# TZ10xx register map
File version: 0.1g
Registers are 32-bit, read-write, reset 0x0 unless marked. A register's access mark holds for its fields unless they carry their own. Offsets are from the block's base; lines under a group give offsets from that group; [hi:lo] are bit positions; {n}, {i} and the like mark numbered series; 'fields as' and 'values as' point back to an identical list; <NAME> marks a mode.

## Memory map
0x00100000 mpier size 0x10000
0x40000000 pmulv size 0x4000
0x40004000 spic size 0x400
0x40021000 rng size 0x80
0x40022000 sramc size 0x80
0x40023000 evm size 0x40
0x40040000 rtclv size 0x1000
0x40041000 advtmr size 0x1000
0x40042000 tmr size 0x1000
0x40043000 wdt size 0x1000
0x40048000 adcc12 size 0x1000
0x40049000 adcc24 size 0x1000
0x4004A000 gconf size 0x400
0x4004B000 gpio0 size 0x1000
0x4004C000 gpio1 size 0x1000
0x4004D000 gpio2 size 0x1000
0x4004E000 gpio3 size 0x1000
0x40064000 uart0 size 0x1000
0x40065000 uart1 size 0x1000
0x40070000 uart2 size 0x1000
0xE000EF34 fpu size 0x14 — Floating Point system registers

## Interrupts
{n} GPIO_Pin{n} (gpio0) (n=0..7)
{n} GPIO_Pin{n} (gpio1) (n=8..15)
{n} GPIO_Pin{n} (gpio2) (n=16..23)
{n} GPIO_Pin{n} (gpio3) (n=24..31)
39 RTC (rtclv)
40 UART0 (uart0)
41 UART1 (uart1)
42 UART2 (uart2)
44 SRAM_M2M (sramc)
45 SRAM_ERR (sramc)
46 SPIC (spic)
56 ADCC12 (adcc12)
57 ADCC24 (adcc24)
59 WDT (wdt)
60 TMR0 (tmr)
61 TMR1 (tmr)
64 ADVTMR0 (advtmr)
65 ADVTMR1 (advtmr)
66 ADVTMR2 (advtmr)
67 ADVTMR3 (advtmr)
68 ADVTMR0_CAP (advtmr)
69 ADVTMR1_CAP (advtmr)
70 ADVTMR2_CAP (advtmr)
71 ADVTMR3_CAP (advtmr)
72 ADVTMR0_CMP (advtmr)
73 ADVTMR1_CMP (advtmr)
74 ADVTMR2_CMP (advtmr)
75 ADVTMR3_CMP (advtmr)
76 PMU_WKUP (pmulv)
77 BOR (pmulv)
79 FPU (fpu)

## mpier
Base 0x00100000
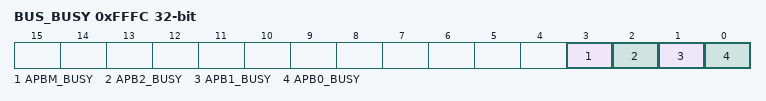
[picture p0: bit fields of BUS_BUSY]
0xFFFC BUS_BUSY ro — Bus busy flag for monitoring whether there are outstanding transactions on APB buses. For detail of procedure for power mode transition using this register, refer to Chapter 2. MCU Power Management Unit.
  [3] APBM_BUSY — APB bus for AESA, RNG, EVM, SRAMC register busy (0x0 : IDLE, 0x1 : BUSY)
  [2] APB2_BUSY — APB2 bus busy (0x0 : IDLE, 0x1 : BUSY)
  [1] APB1_BUSY — APB1 bus busy (0x0 : IDLE, 0x1 : BUSY)
  [0] APB0_BUSY — APB0 bus busy (0x0 : IDLE, 0x1 : BUSY)

## rng
Base 0x40021000
0x00 RNDO ro — Random Number Output Register
  [31:0] RNDO — When [RNDREADY] is 1, 32-bit intrinsic random numbers can be read every time data is read. When [RNDREADY] is 0, 0 can be read. Although this is 0 immediately after reset cancellation, RNDREADY becomes 1 after a while, allowing random numbers to be read through this register.
0x04 RNDREADY ro — Random Number Ready Register
  [0] RNDREADY — 0b0: 0 can be read through [RNDO] because of random numbers being generated. 0b1: Random numbers can be read through [RNDO] since random number generation has been completed. This is 0 immediately after reset cancellation, but becomes 1 after a while.

## sramc
Base 0x40022000
0x00 M2MSTART — M2M activation signal
  [0] START — 1: Activation 0: Invalid * "0" is always returned when data is read
0x04 M2MSTOP
  [0] STOP — 1: Stop 0: Invalid * "0" is always returned when data is read
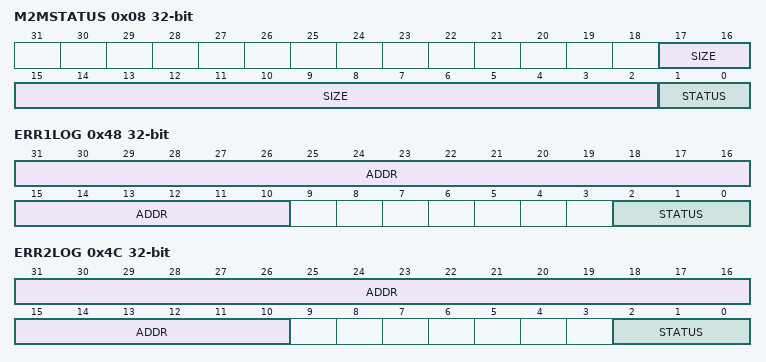
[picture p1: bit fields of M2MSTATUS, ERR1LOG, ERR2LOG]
0x08 M2MSTATUS ro — Status
  [17:2] SIZE — Size of data being currently transferred (amount of data that have been transferred so far)
  [1:0] STATUS — 0b10: Waits for interrupt clearing 0b01: In operation 0b00: Under stop
0x10 M2MSRCADDR — Source address
  [31:2] ADDR — Address from which to read data Set in units of words
0x20 M2MDSTADDR — Destination address
  [31:2] ADDR — Address to which to write data Set in units of words
0x24 M2MSIZE — Transfer size
  [17:2] SIZE — Transfer size settings. The source and destination have the same transfer size. Set in units of words.
0x30 M2MINTEN — Interrupt function ON/OFF
  [0] EN — 1: Interrupt function ON 0: Interrupt function OFF
0x34 M2MINTCLR — Interrupt clearing
  [0] CLR — 1: Activation 0: Invalid * "0" is always returned when data is read.
0x40 ERRINTEN — Error interrupt output function ON/OFF
  [0] EN — 1: Error interrupt output function ON 0: Error interrupt output function OFF
0x44 ERRSTATUS ro — Error cause
  [3:0] STATUS — Error cause indication [3]=1:Error4 occurs [2]=1:Error3 occurs [1]=1:Error2 occurs [0]=1:Error1 occurs
0x48 ERR1LOG ro — Error1 cause
  [31:10] ADDR — Error1 occurrence access globus address (in units of 1kB)
  [2:0] STATUS — Error1 occurrence cause I/F 0b101:S2M 0b100:M2M 0b010:Bus(AHB Port2) 0b001:Bus(AHB Port1) 0b000:Bus(AHB Port0)
0x4C ERR2LOG ro — Error2 cause
  [31:10] ADDR — Error2 occurrence access globus address (in units of 1kB)
  [2:0] STATUS — Error2 occurrence cause I/F 0b100:M2M 0b010:Bus(AHB Port2) 0b001:Bus(AHB Port1) 0b000:Bus(AHB Port0)
0x50 ERRCLR — Error cause detection clearing
  [3:0] CLR — [3]: Clears detection of Error4 cause [2]: Clears detection of Error3 cause [1]: Clears detection of Error2 cause [0]: Clears detection of Error1 cause * "0" is always returned when data is read.
